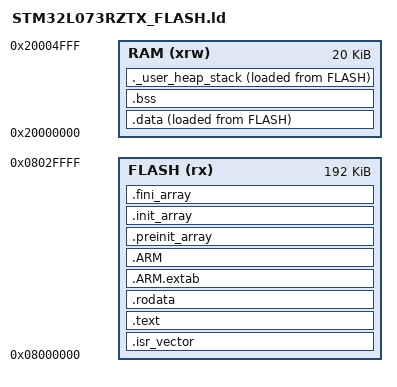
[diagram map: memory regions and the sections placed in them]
/*
******************************************************************************
** Modified linker script with memory permission control
******************************************************************************
*/

/* Entry Point */
ENTRY(Reset_Handler)

/* Highest address of the user mode stack */
_estack = ORIGIN(RAM) + LENGTH(RAM); /* end of "RAM" Ram type memory */

_Min_Heap_Size = 0x200; /* required amount of heap */
_Min_Stack_Size = 0x400; /* required amount of stack */

/* Memories definition */
MEMORY
{
  RAM    (xrw)    : ORIGIN = 0x20000000,   LENGTH = 20K
  FLASH    (rx)    : ORIGIN = 0x8000000,   LENGTH = 192K
}

/* Memory permission definitions */
PHDRS {
  flash PT_LOAD FLAGS(5); /* FLASH RX权限 (0x5 = read|execute) */
  ram PT_LOAD FLAGS(6);   /* RAM RW权限 (0x6 = read|write) */
}

/* Sections */
SECTIONS
{
  /* The startup code into "FLASH" Rom type memory */
  .isr_vector :
  {
    . = ALIGN(4);
    KEEP(*(.isr_vector)) /* Startup code */
    . = ALIGN(4);
  } >FLASH :flash

  /* The program code and other data into "FLASH" Rom type memory */
  .text :
  {
    . = ALIGN(4);
    *(.text)           /* .text sections (code) */
    *(.text*)          /* .text* sections (code) */
    *(.glue_7)         /* glue arm to thumb code */
    *(.glue_7t)        /* glue thumb to arm code */
    *(.eh_frame)

    KEEP (*(.init))
    KEEP (*(.fini))

    . = ALIGN(4);
    _etext = .;        /* define a global symbols at end of code */
  } >FLASH :flash

  /* Constant data into "FLASH" Rom type memory */
  .rodata :
  {
    . = ALIGN(4);
    *(.rodata)         /* .rodata sections (constants, strings, etc.) */
    *(.rodata*)        /* .rodata* sections (constants, strings, etc.) */
    . = ALIGN(4);
  } >FLASH :flash

  .ARM.extab   : {
    . = ALIGN(4);
    *(.ARM.extab* .gnu.linkonce.armextab.*)
    . = ALIGN(4);
  } >FLASH :flash

  .ARM : {
    . = ALIGN(4);
    __exidx_start = .;
    *(.ARM.exidx*)
    __exidx_end = .;
    . = ALIGN(4);
  } >FLASH :flash

  .preinit_array     :
  {
    . = ALIGN(4);
    PROVIDE_HIDDEN (__preinit_array_start = .);
    KEEP (*(.preinit_array*))
    PROVIDE_HIDDEN (__preinit_array_end = .);
    . = ALIGN(4);
  } >FLASH :flash

  .init_array :
  {
    . = ALIGN(4);
    PROVIDE_HIDDEN (__init_array_start = .);
    KEEP (*(SORT(.init_array.*)))
    KEEP (*(.init_array*))
    PROVIDE_HIDDEN (__init_array_end = .);
    . = ALIGN(4);
  } >FLASH :flash

  .fini_array :
  {
    . = ALIGN(4);
    PROVIDE_HIDDEN (__fini_array_start = .);
    KEEP (*(SORT(.fini_array.*)))
    KEEP (*(.fini_array*))
    PROVIDE_HIDDEN (__fini_array_end = .);
    . = ALIGN(4);
  } >FLASH :flash

  /* Used by the startup to initialize data */
  _sidata = LOADADDR(.data);

  /* Initialized data sections into "RAM" Ram type memory */
  .data :
  {
    . = ALIGN(4);
    _sdata = .;        /* create a global symbol at data start */
    *(.data)           /* .data sections */
    *(.data*)          /* .data* sections */
    *(.RamFunc)        /* .RamFunc sections */
    *(.RamFunc*)       /* .RamFunc* sections */

    . = ALIGN(4);
    _edata = .;        /* define a global symbol at data end */
  } >RAM AT> FLASH :ram

  /* Uninitialized data section into "RAM" Ram type memory */
  . = ALIGN(4);
  .bss :
  {
    /* This is used by the startup in order to initialize the .bss section */
    _sbss = .;         /* define a global symbol at bss start */
    __bss_start__ = _sbss;
    *(.bss)
    *(.bss*)
    *(COMMON)

    . = ALIGN(4);
    _ebss = .;         /* define a global symbol at bss end */
    __bss_end__ = _ebss;
  } >RAM :ram

  /* User_heap_stack section */
/* 修改后 */
._user_heap_stack (NOLOAD) :
{
    . = ALIGN(8);
    __heap_start__ = .;
    . = . + _Min_Heap_Size;
    __heap_end__ = .;
    __stack_start__ = .;
    . = . + _Min_Stack_Size;
    . = ALIGN(8);
    __stack_end__ = .;
} >RAM AT>FLASH

  /* Remove information from the compiler libraries */
  /DISCARD/ :
  {
    libc.a ( * )
    libm.a ( * )
    libgcc.a ( * )
  }

  .ARM.attributes 0 : { *(.ARM.attributes) }
}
